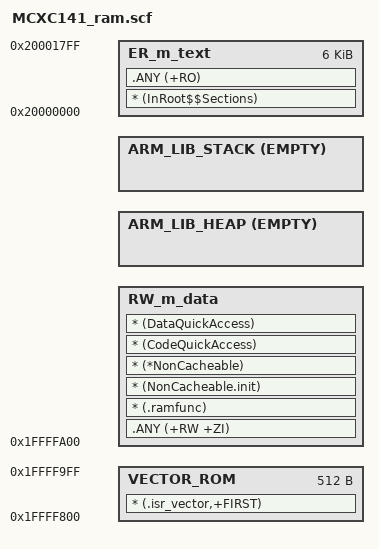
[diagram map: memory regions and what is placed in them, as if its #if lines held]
#!armclang --target=arm-arm-none-eabi -mcpu=cortex-m0plus -E -x c
/*
** ###################################################################
**     Processors:          MCXC141VFM
**                          MCXC141VLH
**
**     Compiler:            Keil ARM C/C++ Compiler
**     Reference manual:    MCXC242RM, Rev.1, Mar 2024
**     Version:             rev. 1.5, 2025-11-07
**     Build:               b251107
**
**     Abstract:
**         Linker file for the Keil ARM C/C++ Compiler
**
**     Copyright 2016 Freescale Semiconductor, Inc.
**     Copyright 2016-2025 NXP
**     SPDX-License-Identifier: BSD-3-Clause
**
**     http:                 www.nxp.com
**     mail:                 support@nxp.com
**
** ###################################################################
*/

#define m_interrupts_start             0x1FFFF800
#define m_interrupts_size              0x00000200

#define m_data_start                   0x1FFFFA00
#define m_data_size                    0x00000600

#define m_text_start                   0x20000000
#define m_text_size                    0x00001800

/* Sizes */
#if (defined(__stack_size__))
  #define Stack_Size                   __stack_size__
#else
  #define Stack_Size                   0x0100
#endif

#if (defined(__heap_size__))
  #define Heap_Size                    __heap_size__
#else
  #define Heap_Size                    0x0100
#endif

LR_m_text m_text_start m_text_size {   ; load region size_region
  ER_m_text m_text_start m_text_size { ; load address = execution address
    * (InRoot$$Sections)
    .ANY (+RO)
  }

  RW_m_data m_data_start m_data_size-Stack_Size-Heap_Size { ; RW data
    .ANY (+RW +ZI)
    * (.ramfunc)
    * (NonCacheable.init)
    * (*NonCacheable)
    * (CodeQuickAccess)
    * (DataQuickAccess)
  }
  ARM_LIB_HEAP +0 EMPTY Heap_Size {    ; Heap region growing up
  }
  ARM_LIB_STACK m_data_start+m_data_size EMPTY -Stack_Size { ; Stack region growing down
  }
}

LR_m_interrupts m_interrupts_start m_interrupts_size {
  VECTOR_ROM m_interrupts_start m_interrupts_size { ; load address = execution address
    * (.isr_vector,+FIRST)
  }
}

